AUTOSAR XML (schema 00046)
package /jmc_auto/ModuleServices/LocalizationApplication
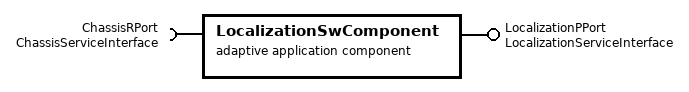
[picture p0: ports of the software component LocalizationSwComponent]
  adaptive application sw component type LocalizationSwComponent
    require port ChassisRPort: required-interface=ChassisServiceInterface
    provide port LocalizationPPort: provided-interface=LocalizationServiceInterface
package /jmc_auto/ModuleServices/LocalizationExecutable
  executable LocalizationExecutable
    root sw component prototype LocalizationRootSwComponent: application-type=LocalizationSwComponent
